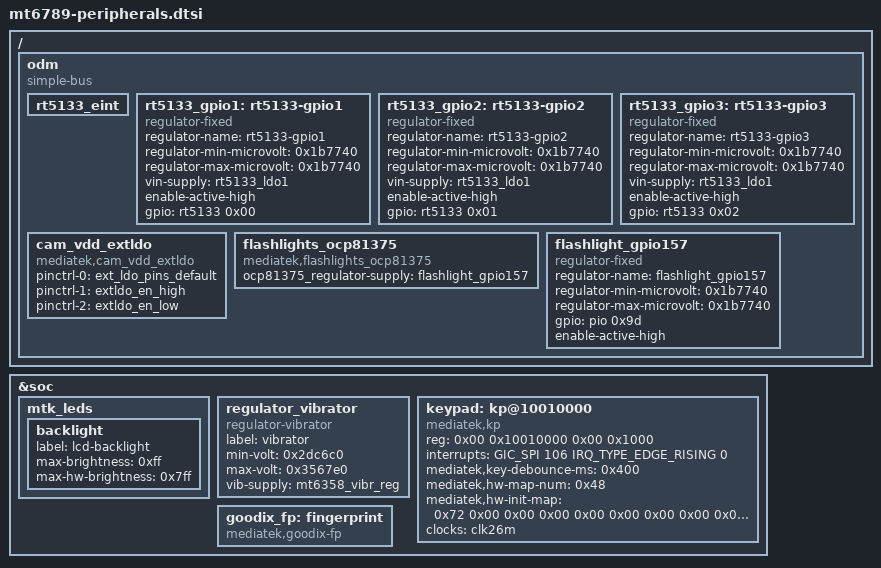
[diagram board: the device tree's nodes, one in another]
// SPDX-License-Identifier: (GPL-2.0 OR MIT)
/* MT6789 peripherals blocks - split out of the soc node by tools/scripts/dts-socsplit.py */

&soc {
	mtk_leds: mtk_leds {

		backlight {
			label = "lcd-backlight";
			max-brightness = <0xff>;
			max-hw-brightness = <0x7ff>;
		};
	};

	regulator_vibrator: regulator_vibrator {
		compatible = "regulator-vibrator";
		label = "vibrator";
		min-volt = <0x2dc6c0>;
		max-volt = <0x3567e0>;
		vib-supply = <&mt6358_vibr_reg>;
	};

	keypad: kp@10010000 {
		compatible = "mediatek,kp";
		reg = <0x00 0x10010000 0x00 0x1000>;
		interrupts = <GIC_SPI 106 IRQ_TYPE_EDGE_RISING 0>;
		mediatek,key-debounce-ms = <0x400>;
		mediatek,hw-map-num = <0x48>;
		mediatek,hw-init-map = <0x72 0x00 0x00 0x00 0x00 0x00 0x00 0x00 0x00 0x00 0x00 0x00 0x00 0x00 0x00 0x00 0x00 0x00 0x00 0x00 0x00 0x00 0x00 0x00 0x00 0x00 0x00 0x00 0x00 0x00 0x00 0x00 0x00 0x00 0x00 0x00 0x00 0x00 0x00 0x00 0x00 0x00 0x00 0x00 0x00 0x00 0x00 0x00 0x00 0x00 0x00 0x00 0x00 0x00 0x00 0x00 0x00 0x00 0x00 0x00 0x00 0x00 0x00 0x00 0x00 0x00 0x00 0x00 0x00 0x00 0x00 0x00>;
		clocks = <&clk26m>;
		clock-names = "kpd";
	};

	goodix_fp: fingerprint {
		compatible = "mediatek,goodix-fp";
	};

};

/ {
	odm: odm {
		compatible = "simple-bus";

		rt5133_eint: rt5133_eint {
		};

		rt5133_gpio1: rt5133-gpio1 {
			compatible = "regulator-fixed";
			regulator-name = "rt5133-gpio1";
			regulator-min-microvolt = <0x1b7740>;
			regulator-max-microvolt = <0x1b7740>;
			vin-supply = <&rt5133_ldo1>;
			enable-active-high;
			gpio = <&rt5133 0x00 0x00>;
		};

		rt5133_gpio2: rt5133-gpio2 {
			compatible = "regulator-fixed";
			regulator-name = "rt5133-gpio2";
			regulator-min-microvolt = <0x1b7740>;
			regulator-max-microvolt = <0x1b7740>;
			vin-supply = <&rt5133_ldo1>;
			enable-active-high;
			gpio = <&rt5133 0x01 0x00>;
		};

		rt5133_gpio3: rt5133-gpio3 {
			compatible = "regulator-fixed";
			regulator-name = "rt5133-gpio3";
			regulator-min-microvolt = <0x1b7740>;
			regulator-max-microvolt = <0x1b7740>;
			vin-supply = <&rt5133_ldo1>;
			enable-active-high;
			gpio = <&rt5133 0x02 0x00>;
		};

		cam_vdd_extldo: cam_vdd_extldo {
			compatible = "mediatek,cam_vdd_extldo";
			pinctrl-names = "extldodefault", "extldo_en_high", "extldo_en_low";
			pinctrl-0 = <&ext_ldo_pins_default>;
			pinctrl-1 = <&extldo_en_high>;
			pinctrl-2 = <&extldo_en_low>;
			status = "okay";
		};

		flashlights_ocp81375: flashlights_ocp81375 {
			compatible = "mediatek,flashlights_ocp81375";
			status = "okay";
			ocp81375_regulator-supply = <&flashlight_gpio157>;
		};

		flashlight_gpio157: flashlight_gpio157 {
			compatible = "regulator-fixed";
			regulator-name = "flashlight_gpio157";
			regulator-min-microvolt = <0x1b7740>;
			regulator-max-microvolt = <0x1b7740>;
			gpio = <&pio 0x9d 0x00>;
			enable-active-high;
		};
	};
};
